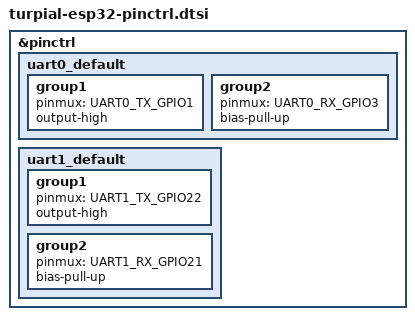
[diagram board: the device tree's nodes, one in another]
/*
 * Copyright (c) 2026 Jean-Pierre De Jesus DIAZ <me@jeandudey.tech>
 *
 * SPDX-License-Identifier: Apache-2.0
 */

#include <zephyr/dt-bindings/pinctrl/esp-pinctrl-common.h>
#include <zephyr/dt-bindings/pinctrl/esp32-pinctrl.h>
#include <zephyr/dt-bindings/pinctrl/esp32-gpio-sigmap.h>

&pinctrl {
	uart0_default: uart0_default {
		group1 {
			pinmux = <UART0_TX_GPIO1>;
			output-high;
		};

		group2 {
			pinmux = <UART0_RX_GPIO3>;
			bias-pull-up;
		};
	};

	uart1_default: uart1_default {
		group1 {
			pinmux = <UART1_TX_GPIO22>;
			output-high;
		};

		group2 {
			pinmux = <UART1_RX_GPIO21>;
			bias-pull-up;
		};
	};
};
